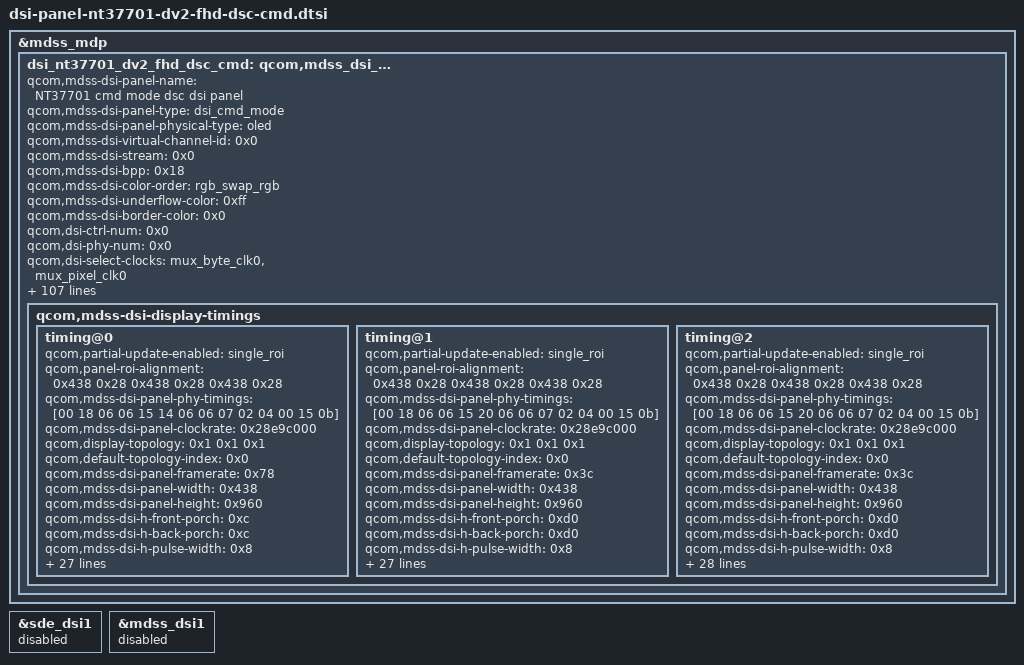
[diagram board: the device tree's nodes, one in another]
/* Copyright (c) 2014, Code Aurora Forum. All rights reserved.
 *
 * This program is free software; you can redistribute it and/or modify
 * it under the terms of the GNU General Public License version 2 and
 * only version 2 as published by the Free Software Foundation.
 *
 * This program is distributed in the hope that it will be useful,
 * but WITHOUT ANY WARRANTY; without even the implied warranty of
 * MERCHANTABILITY or FITNESS FOR A PARTICULAR PURPOSE.  See the
 * GNU General Public License for more details.
 */

&mdss_mdp {
    dsi_nt37701_dv2_fhd_dsc_cmd: qcom,mdss_dsi_nt37701_dv1_fhd_dsc_cmd {
        qcom,mdss-dsi-panel-name = "NT37701 cmd mode dsc dsi panel";
				qcom,mdss-dsi-panel-type = "dsi_cmd_mode";
				qcom,mdss-dsi-panel-physical-type = "oled";
				qcom,mdss-dsi-virtual-channel-id = <0x0>;
				qcom,mdss-dsi-stream = <0x0>;
				qcom,mdss-dsi-bpp = <0x18>;
				qcom,mdss-dsi-color-order = "rgb_swap_rgb";
				qcom,mdss-dsi-underflow-color = <0xff>;
				qcom,mdss-dsi-border-color = <0x0>;
				qcom,dsi-ctrl-num = <0x0>;
				qcom,dsi-phy-num = <0x0>;
				qcom,dsi-select-clocks = "mux_byte_clk0", "mux_pixel_clk0";
				qcom,mdss-dsi-traffic-mode = "burst_mode";
				qcom,mdss-dsi-lane-map = "lane_map_0123";
				qcom,mdss-dsi-bllp-eof-power-mode;
				qcom,mdss-dsi-bllp-power-mode;
				qcom,mdss-dsi-lane-0-state;
				qcom,mdss-dsi-lane-1-state;
				qcom,mdss-dsi-lane-2-state;
				qcom,mdss-dsi-lane-3-state;
				qcom,mdss-dsi-reset-sequence = <0x1 0xa 0x0 0x2 0x1 0xa>;
				lge,mdss-dsi-reset-keep-high-after-off-cmd = <0xb4>;
				qcom,mdss-dsi-dma-trigger = "trigger_sw";
				qcom,mdss-dsi-mdp-trigger = "none";
				qcom,mdss-dsi-te-pin-select = <0x1>;
				qcom,mdss-dsi-wr-mem-start = <0x2c>;
				qcom,mdss-dsi-wr-mem-continue = <0x3c>;
				qcom,mdss-dsi-te-dcs-command = <0x1>;
				qcom,mdss-dsi-lp11-init;
				qcom,mdss-dsi-tx-eot-append;
				qcom,ulps-enabled;
				qcom,mdss-pan-physical-width-dimension = <0x47>;
				qcom,mdss-pan-physical-height-dimension = <0x9d>;
				qcom,mdss-dsi-panel-hdr-enabled;
				qcom,mdss-dsi-panel-hdr-color-primaries = <0x3a20 0x3e3f 0x7eb3 0x40ab 0x3a61 0x78be 0x1e6e 0xd57>;
				qcom,mdss-dsi-panel-peak-brightness = <0x4c4b40>;
				qcom,mdss-dsi-panel-blackness-level = <0x17f6>;
				lge,blmap = <0x0 0x2c 0x2c 0x2c 0x2c 0x2c 0x2c 0x2c 0x2c 0x2c 0x2c 0x34 0x3b 0x43 0x4a 0x52 0x59 0x61 0x69 0x70 0x78 0x7f 0x87 0x8f 0x96 0x9e 0xa5 0xad 0xb4 0xbc 0xc4 0xcb 0xd3 0xda 0xe2 0xe9 0xf1 0xfd 0x109 0x115 0x121 0x12d 0x139 0x144 0x150 0x15c 0x168 0x174 0x180 0x18c 0x198 0x1a4 0x1b0 0x1bc 0x1c8 0x1d3 0x1df 0x1eb 0x1f7 0x203 0x20f 0x21b 0x22a 0x238 0x247 0x255 0x264 0x272 0x281 0x28f 0x29e 0x2ac 0x2bb 0x2ca 0x2d8 0x2e7 0x2f5 0x304 0x312 0x321 0x32f 0x33e 0x34e 0x35d 0x36d 0x378 0x388 0x398 0x3a7 0x3b7 0x3c7 0x3d7 0x3e6 0x3f6 0x406 0x416 0x426 0x435 0x445 0x455 0x465 0x475 0x484 0x494 0x4a4 0x4b4 0x4c3 0x4d3 0x4e3 0x4f0 0x4fe 0x50b 0x518 0x526 0x533 0x540 0x54e 0x55b 0x568 0x576 0x583 0x591 0x59e 0x5ab 0x5b9 0x5c6 0x5d3 0x5e1 0x5ee 0x5fb 0x609 0x616 0x623 0x631 0x63e 0x64e 0x65d 0x66d 0x67d 0x68c 0x69c 0x6ac 0x6b9 0x6c9 0x6d8 0x6e8 0x6f8 0x708 0x717 0x727 0x737 0x746 0x756 0x766 0x775 0x785 0x795 0x7a4 0x7b4 0x7c6 0x7d3 0x7e1 0x7ee 0x7fc 0x809 0x817 0x824 0x832 0x83f 0x84d 0x85a 0x868 0x875 0x882 0x890 0x89d 0x8ab 0x8b8 0x8c6 0x8d3 0x8e1 0x8ee 0x8fc 0x909 0x917 0x924 0x932 0x93f 0x94d 0x95a 0x968 0x975 0x983 0x990 0x99e 0x9ac 0x9b9 0x9c7 0x9d4 0x9e2 0x9ef 0x9fd 0xa0a 0xa18 0xa25 0xa33 0xa40 0xa4e 0xa5b 0xa68 0xa76 0xa83 0xa90 0xa9d 0xaab 0xab8 0xac5 0xad2 0xae0 0xaed 0xafa 0xb07 0xb15 0xb22 0xb2f 0xb3c 0xb4a 0xb57 0xb64 0xb71 0xb7f 0xb8c 0xb99 0xba8 0xbb7 0xbc6 0xbd5 0xbe4 0xbf3 0xc02 0xc11 0xc20 0xc2f 0xc3e 0xc4e 0xc5d 0xc6c 0xc7b 0xc8a 0xc99 0xca8 0xcb7 0xcc6 0xcd5 0xce4 0xcf3 0xcf7 0xcfc 0xd00 0xd04 0xd08 0xd0d 0xd11 0xd15 0xd19 0xd1e 0xd22 0xd26 0xd2a 0xd2f 0xd33 0xd37 0xd3b 0xd40 0xd44 0xd48 0xd4f 0xd55 0xd5c 0xd63 0xd69 0xd70 0xd77 0xd7d 0xd84 0xd8b 0xd91 0xd98 0xd9f 0xda5 0xdac 0xdb3 0xdb9 0xdc0 0xdc7 0xdcd 0xdd4 0xddb 0xde1 0xde8 0xdef 0xdf5 0xdfc 0xe03 0xe09 0xe10 0xe17 0xe1d 0xe24 0xe2b 0xe31 0xe38 0xe3f 0xe45 0xe4c 0xe53 0xe59 0xe60 0xe67 0xe6d 0xe74 0xe7b 0xe81 0xe88 0xe8f 0xe95 0xe9c 0xea3 0xea9 0xeb0 0xeb7 0xebd 0xec4 0xecb 0xed1 0xed8 0xedf 0xee5 0xeec 0xef3 0xef9 0xf00 0xf07 0xf0d 0xf14 0xf1b 0xf21 0xf28 0xf2f 0xf35 0xf3c 0xf3d 0xf3f 0xf40 0xf42 0xf43 0xf45 0xf46 0xf48 0xf49 0xf4b 0xf4c 0xf4e 0xf4f 0xf51 0xf52>;
				lge,blmap-daylight = <0x0 0x2c 0x2c 0x2c 0x2c 0x2c 0x2c 0x2c 0x2c 0x2c 0x2c 0x34 0x3b 0x43 0x4a 0x52 0x59 0x61 0x69 0x70 0x78 0x7f 0x87 0x8f 0x96 0x9e 0xa5 0xad 0xb4 0xbc 0xc4 0xcb 0xd3 0xda 0xe2 0xe9 0xf1 0xfd 0x109 0x115 0x121 0x12d 0x139 0x144 0x150 0x15c 0x168 0x174 0x180 0x18c 0x198 0x1a4 0x1b0 0x1bc 0x1c8 0x1d3 0x1df 0x1eb 0x1f7 0x203 0x20f 0x21b 0x22a 0x238 0x247 0x255 0x264 0x272 0x281 0x28f 0x29e 0x2ac 0x2bb 0x2ca 0x2d8 0x2e7 0x2f5 0x304 0x312 0x321 0x32f 0x33e 0x34e 0x35d 0x36d 0x378 0x388 0x398 0x3a7 0x3b7 0x3c7 0x3d7 0x3e6 0x3f6 0x406 0x416 0x426 0x435 0x445 0x455 0x465 0x475 0x484 0x494 0x4a4 0x4b4 0x4c3 0x4d3 0x4e3 0x4f0 0x4fe 0x50b 0x518 0x526 0x533 0x540 0x54e 0x55b 0x568 0x576 0x583 0x591 0x59e 0x5ab 0x5b9 0x5c6 0x5d3 0x5e1 0x5ee 0x5fb 0x609 0x616 0x623 0x631 0x63e 0x64e 0x65d 0x66d 0x67d 0x68c 0x69c 0x6ac 0x6b9 0x6c9 0x6d8 0x6e8 0x6f8 0x708 0x717 0x727 0x737 0x746 0x756 0x766 0x775 0x785 0x795 0x7a4 0x7b4 0x7c6 0x7d3 0x7e1 0x7ee 0x7fc 0x809 0x817 0x824 0x832 0x83f 0x84d 0x85a 0x868 0x875 0x882 0x890 0x89d 0x8ab 0x8b8 0x8c6 0x8d3 0x8e1 0x8ee 0x8fc 0x909 0x917 0x924 0x932 0x93f 0x94d 0x95a 0x968 0x975 0x983 0x990 0x99e 0x9ac 0x9b9 0x9c7 0x9d4 0x9e2 0x9ef 0x9fd 0xa0a 0xa18 0xa25 0xa33 0xa40 0xa4e 0xa5b 0xa68 0xa76 0xa83 0xa90 0xa9d 0xaab 0xab8 0xac5 0xad2 0xae0 0xaed 0xafa 0xb07 0xb15 0xb22 0xb2f 0xb3c 0xb4a 0xb57 0xb64 0xb71 0xb7f 0xb8c 0xb99 0xbc2 0xbec 0xc15 0xc3f 0xc68 0xc92 0xcbb 0xce4 0xd0e 0xd37 0xd61 0xd8a 0xdb4 0xddd 0xe07 0xe30 0xe59 0xe83 0xeac 0xed6 0xeff 0xf29 0xf52 0xf52 0xf52 0xf52 0xf52 0xf52 0xf52 0xf52 0xf52 0xf52 0xf52 0xf52 0xf52 0xf52 0xf52 0xf52 0xf52 0xf52 0xf52 0xf52 0xf52 0xf52 0xf52 0xf52 0xf52 0xf52 0xf52 0xf52 0xf52 0xf52 0xf52 0xf52 0xf52 0xf52 0xf52 0xf52 0xf52 0xf52 0xf52 0xf52 0xf52 0xf52 0xf52 0xf52 0xf52 0xf52 0xf52 0xf52 0xf52 0xf52 0xf52 0xf52 0xf52 0xf52 0xf52 0xf52 0xf52 0xf52 0xf52 0xf52 0xf52 0xf52 0xf52 0xf52 0xf52 0xf52 0xf52 0xf52 0xf52 0xf52 0xf52 0xf52 0xf52 0xf52 0xf52 0xf52 0xf52 0xf52 0xf52 0xf52 0xf52 0xf52 0xf52 0xf52 0xf52 0xf52 0xf52 0xf52 0xf52 0xf52 0xf52 0xf52 0xf52 0xf52 0xf52 0xf52 0xf52 0xf52 0xf52 0xf52 0xf52 0xf52 0xf52 0xf52 0xf52 0xf52 0xf52 0xf52 0xf52 0xf52 0xf52>;
				lge,blmap-hdr = <0x0 0x2c 0x2c 0x2c 0x2c 0x2c 0x2c 0x2c 0x2c 0x2c 0x2c 0x34 0x3b 0x43 0x4a 0x52 0x59 0x61 0x69 0x70 0x78 0x7f 0x87 0x8f 0x96 0x9e 0xa5 0xad 0xb4 0xbc 0xc4 0xcb 0xd3 0xda 0xe2 0xe9 0xf1 0xfd 0x109 0x115 0x121 0x12d 0x139 0x144 0x150 0x15c 0x168 0x174 0x180 0x18c 0x198 0x1a4 0x1b0 0x1bc 0x1c8 0x1d3 0x1df 0x1eb 0x1f7 0x203 0x20f 0x21b 0x22a 0x238 0x247 0x255 0x264 0x272 0x281 0x28f 0x29e 0x2ac 0x2bb 0x2ca 0x2d8 0x2e7 0x2f5 0x304 0x312 0x321 0x32f 0x33e 0x34e 0x35d 0x36d 0x378 0x388 0x398 0x3a7 0x3b7 0x3c7 0x3d7 0x3e6 0x3f6 0x406 0x416 0x426 0x435 0x445 0x455 0x465 0x475 0x484 0x494 0x4a4 0x4b4 0x4c3 0x4d3 0x4e3 0x4f0 0x4fe 0x50b 0x518 0x526 0x533 0x540 0x54e 0x55b 0x568 0x576 0x583 0x591 0x59e 0x5ab 0x5b9 0x5c6 0x5d3 0x5e1 0x5ee 0x5fb 0x609 0x616 0x623 0x631 0x63e 0x64e 0x65d 0x66d 0x67d 0x68c 0x69c 0x6ac 0x6b9 0x6c9 0x6d8 0x6e8 0x6f8 0x708 0x717 0x727 0x737 0x746 0x756 0x766 0x775 0x785 0x795 0x7a4 0x7b4 0x7c6 0x7d3 0x7e1 0x7ee 0x7fc 0x809 0x817 0x824 0x832 0x83f 0x84d 0x85a 0x868 0x875 0x882 0x890 0x89d 0x8ab 0x8b8 0x8c6 0x8d3 0x8e1 0x8ee 0x8fc 0x909 0x917 0x924 0x932 0x93f 0x94d 0x95a 0x968 0x975 0x983 0x990 0x99e 0x9ac 0x9b9 0x9c7 0x9d4 0x9e2 0x9ef 0x9fd 0xa0a 0xa18 0xa25 0xa33 0xa40 0xa4e 0xa5b 0xa68 0xa76 0xa83 0xa90 0xa9d 0xaab 0xab8 0xac5 0xad2 0xae0 0xaed 0xafa 0xb07 0xb15 0xb22 0xb2f 0xb3c 0xb4a 0xb57 0xb64 0xb71 0xb7f 0xb8c 0xb99 0xba8 0xbb7 0xbc6 0xbd5 0xbe4 0xbf3 0xc02 0xc11 0xc20 0xc2f 0xc3e 0xc4e 0xc5d 0xc6c 0xc7b 0xc8a 0xc99 0xca8 0xcb7 0xcc6 0xcd5 0xce4 0xcf3 0xcf7 0xcfc 0xd00 0xd04 0xd08 0xd0d 0xd11 0xd15 0xd19 0xd1e 0xd22 0xd26 0xd2a 0xd2f 0xd33 0xd37 0xd3b 0xd40 0xd44 0xd48 0xd4f 0xd55 0xd5c 0xd63 0xd69 0xd70 0xd77 0xd7d 0xd84 0xd8b 0xd91 0xd98 0xd9f 0xda5 0xdac 0xdb3 0xdb9 0xdc0 0xdc7 0xdcd 0xdd4 0xddb 0xde1 0xde8 0xdef 0xdf5 0xdfc 0xe03 0xe09 0xe10 0xe17 0xe1d 0xe24 0xe2b 0xe31 0xe38 0xe3f 0xe45 0xe4c 0xe53 0xe59 0xe60 0xe67 0xe6d 0xe74 0xe7b 0xe81 0xe88 0xe8f 0xe95 0xe9c 0xea3 0xea9 0xeb0 0xeb7 0xebd 0xec4 0xecb 0xed1 0xed8 0xedf 0xee5 0xeec 0xef3 0xef9 0xf00 0xf07 0xf0d 0xf14 0xf1b 0xf21 0xf28 0xf2f 0xf35 0xf3c 0xf3d 0xf3f 0xf40 0xf42 0xf43 0xf45 0xf46 0xf48 0xf49 0xf4b 0xf4c 0xf4e 0xf4f 0xf51 0xf52>;
				lge,blmap-hdr-daylight = <0x0 0x2c 0x2c 0x2c 0x2c 0x2c 0x2c 0x2c 0x2c 0x2c 0x2c 0x34 0x3b 0x43 0x4a 0x52 0x59 0x61 0x69 0x70 0x78 0x7f 0x87 0x8f 0x96 0x9e 0xa5 0xad 0xb4 0xbc 0xc4 0xcb 0xd3 0xda 0xe2 0xe9 0xf1 0xfd 0x109 0x115 0x121 0x12d 0x139 0x144 0x150 0x15c 0x168 0x174 0x180 0x18c 0x198 0x1a4 0x1b0 0x1bc 0x1c8 0x1d3 0x1df 0x1eb 0x1f7 0x203 0x20f 0x21b 0x22a 0x238 0x247 0x255 0x264 0x272 0x281 0x28f 0x29e 0x2ac 0x2bb 0x2ca 0x2d8 0x2e7 0x2f5 0x304 0x312 0x321 0x32f 0x33e 0x34e 0x35d 0x36d 0x378 0x388 0x398 0x3a7 0x3b7 0x3c7 0x3d7 0x3e6 0x3f6 0x406 0x416 0x426 0x435 0x445 0x455 0x465 0x475 0x484 0x494 0x4a4 0x4b4 0x4c3 0x4d3 0x4e3 0x4f0 0x4fe 0x50b 0x518 0x526 0x533 0x540 0x54e 0x55b 0x568 0x576 0x583 0x591 0x59e 0x5ab 0x5b9 0x5c6 0x5d3 0x5e1 0x5ee 0x5fb 0x609 0x616 0x623 0x631 0x63e 0x64e 0x65d 0x66d 0x67d 0x68c 0x69c 0x6ac 0x6b9 0x6c9 0x6d8 0x6e8 0x6f8 0x708 0x717 0x727 0x737 0x746 0x756 0x766 0x775 0x785 0x795 0x7a4 0x7b4 0x7c6 0x7d3 0x7e1 0x7ee 0x7fc 0x809 0x817 0x824 0x832 0x83f 0x84d 0x85a 0x868 0x875 0x882 0x890 0x89d 0x8ab 0x8b8 0x8c6 0x8d3 0x8e1 0x8ee 0x8fc 0x909 0x917 0x924 0x932 0x93f 0x94d 0x95a 0x968 0x975 0x983 0x990 0x99e 0x9ac 0x9b9 0x9c7 0x9d4 0x9e2 0x9ef 0x9fd 0xa0a 0xa18 0xa25 0xa33 0xa40 0xa4e 0xa5b 0xa68 0xa76 0xa83 0xa90 0xa9d 0xaab 0xab8 0xac5 0xad2 0xae0 0xaed 0xafa 0xb07 0xb15 0xb22 0xb2f 0xb3c 0xb4a 0xb57 0xb64 0xb71 0xb7f 0xb8c 0xb99 0xbc2 0xbec 0xc15 0xc3f 0xc68 0xc92 0xcbb 0xce4 0xd0e 0xd37 0xd61 0xd8a 0xdb4 0xddd 0xe07 0xe30 0xe59 0xe83 0xeac 0xed6 0xeff 0xf29 0xf52 0xf52 0xf52 0xf52 0xf52 0xf52 0xf52 0xf52 0xf52 0xf52 0xf52 0xf52 0xf52 0xf52 0xf52 0xf52 0xf52 0xf52 0xf52 0xf52 0xf52 0xf52 0xf52 0xf52 0xf52 0xf52 0xf52 0xf52 0xf52 0xf52 0xf52 0xf52 0xf52 0xf52 0xf52 0xf52 0xf52 0xf52 0xf52 0xf52 0xf52 0xf52 0xf52 0xf52 0xf52 0xf52 0xf52 0xf52 0xf52 0xf52 0xf52 0xf52 0xf52 0xf52 0xf52 0xf52 0xf52 0xf52 0xf52 0xf52 0xf52 0xf52 0xf52 0xf52 0xf52 0xf52 0xf52 0xf52 0xf52 0xf52 0xf52 0xf52 0xf52 0xf52 0xf52 0xf52 0xf52 0xf52 0xf52 0xf52 0xf52 0xf52 0xf52 0xf52 0xf52 0xf52 0xf52 0xf52 0xf52 0xf52 0xf52 0xf52 0xf52 0xf52 0xf52 0xf52 0xf52 0xf52 0xf52 0xf52 0xf52 0xf52 0xf52 0xf52 0xf52 0xf52 0xf52 0xf52 0xf52 0xf52 0xf52>;
				lge,blmap-ex = <0x0 0x154 0x154 0x154 0x154 0x154 0x154 0x154 0x154 0x154 0x16a 0x180 0x196 0x1ac 0x1c2 0x1d8 0x1ee 0x204 0x21a 0x230 0x246 0x25c 0x272 0x288 0x29e 0x2b4 0x2ca 0x2e0 0x2f6 0x30c 0x322 0x338 0x34e 0x364 0x37a 0x390 0x3a6 0x3ba 0x3ce 0x3e2 0x3f6 0x40a 0x41e 0x431 0x445 0x459 0x46d 0x481 0x495 0x4a9 0x4bd 0x4d1 0x4e5 0x4f9 0x50d 0x521 0x534 0x548 0x55c 0x570 0x584 0x598 0x5ac 0x5c0 0x5d4 0x5e8 0x5fc 0x610 0x624 0x637 0x64b 0x65f 0x673 0x687 0x69b 0x6af 0x6d2 0x6f4 0x717 0x73a 0x75d 0x77f 0x7a2 0x7c5 0x7e8 0x80a 0x82d 0x850 0x872 0x895 0x8b8 0x8db 0x8fd 0x920 0x943 0x966 0x988 0x9ab 0x9ca 0x9e8 0xa07 0xa25 0xa44 0xa63 0xa81 0xaa0 0xabf 0xadd 0xafc 0xb1a 0xb39 0xb58 0xb76 0xb95 0xbb3 0xbd2 0xbe9 0xc01 0xc18 0xc30 0xc47 0xc5f 0xc76 0xc8e 0xca5 0xcbd 0xcd4 0xcec 0xd03 0xd1b 0xd32 0xd4a 0xd61 0xd79 0xd90 0xdc4 0xdf8 0xe2c 0xe5f 0xe93 0xec7 0xed7 0xee8 0xef8 0xf09 0xf19 0xf2a 0xf3a 0xf4a 0xf5b 0xf6b 0xf7c 0xf8c 0xf9c 0xfad 0xfbd 0xfce 0xfde 0xfef 0xfff 0xfff 0xfff 0xfff 0xfff 0xfff 0xfff 0xfff 0xfff 0xfff 0xfff 0xfff 0xfff 0xfff 0xfff 0xfff 0xfff 0xfff 0xfff 0xfff 0xfff 0xfff 0xfff 0xfff 0xfff 0xfff 0xfff 0xfff 0xfff 0xfff 0xfff 0xfff 0xfff 0xfff 0xfff 0xfff 0xfff 0xfff 0xfff 0xfff 0xfff 0xfff 0xfff 0xfff 0xfff 0xfff 0xfff 0xfff 0xfff 0xfff 0xfff 0xfff 0xfff 0xfff 0xfff 0xfff 0xfff 0xfff 0xfff 0xfff 0xfff 0xfff 0xfff 0xfff 0xfff 0xfff 0xfff 0xfff 0xfff 0xfff 0xfff 0xfff 0xfff 0xfff 0xfff 0xfff 0xfff 0xfff 0xfff 0xfff 0xfff 0xfff 0xfff 0xfff 0xfff 0xfff 0xfff 0xfff 0xfff 0xfff 0xfff 0xfff 0xfff 0xfff 0xfff 0xfff 0xfff 0xfff 0xfff 0xfff 0xfff 0xfff 0xfff 0xfff 0xfff 0xfff 0xfff 0xfff 0xfff 0xfff 0xfff 0xfff 0xfff 0xfff 0xfff 0xfff 0xfff>;
				lge,use-vr-lp-mode;
				lge,mdss-dsi-vr-lp-mode-on-command = [39 00 00 00 00 00 06 f0 55 aa 52 08 00 39 00 00 00 00 00 10 b2 11 00 20 20 00 08 08 00 00 40 30 00 00 00 00 15 00 00 00 00 00 02 6f 0f 39 00 00 00 00 00 0c b2 30 20 24 24 24 24 2f ff 00 00 00 39 01 00 00 00 00 06 f0 55 aa 52 00 00];
				lge,mdss-dsi-vr-lp-mode-off-command = [39 00 00 00 00 00 06 f0 55 aa 52 08 00 39 00 00 00 00 00 10 b2 01 00 20 20 00 08 08 00 00 40 30 00 00 00 00 15 00 00 00 00 00 02 6f 0f 39 00 00 00 00 00 0c b2 30 20 25 89 25 89 2f ff 00 00 00 39 01 00 00 00 00 06 f0 55 aa 52 00 00];
				lge,mdss-dsi-vr-lp-command-state = "dsi_lp_mode";
				lge,blmap-vr = <0x0 0x424>;
				lge,use-color-manager;
				lge,color-manager-default-status = <0x1>;
				lge,mdss-dsi-color-manager-mode-table = <0x0 0x1 0x1 0x1 0x2 0x1 0x3 0x1>;
				lge,mdss-dsi-disp-ctrl-command-1 = [15 01 00 00 00 00 02 55 00];
				lge,mdss-dsi-disp-ctrl-command-1-state = "dsi_lp_mode";
				lge,mdss-dsi-saturation-command = [39 00 00 00 00 00 06 f0 55 aa 52 08 00 39 00 00 00 00 00 2e d1 35 35 35 35 32 30 30 30 32 2d 2d 29 29 32 32 35 35 35 35 33 32 33 35 35 03 01 01 01 01 01 01 01 02 01 01 01 01 06 0c 03 09 0f 68 88 00 39 01 00 00 00 00 06 f0 55 aa 52 00 00];
				lge,mdss-dsi-saturation-command-state = "dsi_hs_mode";
				lge,mdss-dsi-hue-command = [39 00 00 00 00 00 06 f0 55 aa 52 08 00 39 00 00 00 00 00 34 d2 77 0c 40 80 80 8e 80 80 80 80 40 40 40 80 80 80 ad ad a0 80 80 80 80 80 80 80 80 80 80 80 80 80 80 80 80 80 80 80 80 80 80 80 80 80 80 80 80 80 80 80 80 39 01 00 00 00 00 06 f0 55 aa 52 00 00];
				lge,mdss-dsi-hue-command-state = "dsi_hs_mode";
				lge,mdss-dsi-sharpness-command = <0x39000000 0x6f0 0x55aa5208 0x390000 0x7 0xd3020000 0x1100039 0x1000000 0x6f055 0xaa520000>;
				lge,mdss-dsi-sharpness-command-state = "dsi_hs_mode";
				lge,mdss-dsi-cm-natural = <0x39000000 0x6f0 0x55aa5208 0x150000 0x2 0x6f003900 0x0 0x13ce0040 0x4040403d 0x3d3d3d40 0x40404040 0x40404040 0x15000000 0x26f 0x13390000 0x12 0xce454545 0x45454545 0x45454545 0x45454545 0x45401500 0x0 0x26f2439 0x0 0x12ce42 0x42424242 0x42424242 0x42424242 0x42424040 0x15000000 0x26f 0x35390000 0x12 0xce404040 0x40404040 0x40404040 0x40404040 0x40403900 0x0 0x2ed13233 0x32353230 0x302f2d2d 0x2d292929 0x32353535 0x35333233 0x35350301 0x1010101 0x1010201 0x1010106 0xc03090f 0x68880039 0x0 0x34d277 0xc408080 0x7f808080 0x80808080 0x808080a8 0xa8a08080 0x80808080 0x80808080 0x80808080 0x80804040 0x80808080 0x80808080 0x80808080 0x80803900 0x0 0x7d30000 0x0 0x39000000 0x6f0 0x55aa5208 0x7390000 0x3 0xc0010a39 0x1000000 0x6f055 0xaa520000>;
				lge,mdss-dsi-cm-natural-state = "dsi_hs_mode";
				lge,mdss-dsi-cm-vivid = <0x39000000 0x6f0 0x55aa5208 0x150000 0x2 0x6f003900 0x0 0x13ce0040 0x40404040 0x40404040 0x40404040 0x40404040 0x15000000 0x26f 0x13390000 0x12 0xce404040 0x40404040 0x40404040 0x40404040 0x40401500 0x0 0x26f2439 0x0 0x12ce40 0x40404040 0x40404040 0x40404040 0x40404040 0x15000000 0x26f 0x35390000 0x12 0xce404040 0x40404040 0x40404040 0x40404040 0x40403900 0x0 0x2ed15035 0x35355050 0x50505050 0x50505050 0x50505050 0x50505050 0x50500101 0x1010101 0x1010101 0x1010006 0xc03090f 0x68880039 0x0 0x34d277 0xc408080 0x95808080 0x80808080 0x80808080 0x80808080 0x80808080 0x80808080 0x80808080 0x80808080 0x80808080 0x80808080 0x80808080 0x80803900 0x0 0x7d30000 0x0 0x39000000 0x6f0 0x55aa5208 0x7390000 0x3 0xc0010a39 0x1000000 0x6f055 0xaa520000>;
				lge,mdss-dsi-cm-vivid-state = "dsi_hs_mode";
				lge,mdss-dsi-cm-cinema = <0x39000000 0x6f0 0x55aa5208 0x150000 0x2 0x6f003900 0x0 0x13ce0040 0x40444444 0x44444444 0x44444444 0x44444440 0x15000000 0x26f 0x13390000 0x12 0xce404040 0x40404040 0x40404040 0x40404040 0x40401500 0x0 0x26f2439 0x0 0x12ce43 0x43434343 0x43434343 0x43434848 0x48484850 0x15000000 0x26f 0x35390000 0x12 0xce444444 0x44444444 0x44444444 0x44444444 0x44453900 0x0 0x2ed13535 0x35353535 0x37373835 0x302c2c2c 0x30323535 0x35353534 0x33354414 0x11111111 0x11151111 0x21440006 0xc03090f 0x68880039 0x0 0x34d277 0xc408080 0x8d858080 0x70605060 0x7a808080 0x8a8a8a80 0x7b7b7876 0x74808080 0x80808080 0x80808080 0x80808080 0x80808080 0x80808080 0x80803900 0x0 0x7d30000 0x0 0x39000000 0x6f0 0x55aa5208 0x7390000 0x3 0xc0010a39 0x1000000 0x6f055 0xaa520000>;
				lge,mdss-dsi-cm-cinema-state = "dsi_hs_mode";
				lge,mdss-dsi-ve-on-command = [39 00 00 00 00 00 06 f0 55 aa 52 08 00 39 00 00 00 00 00 2e d1 40 40 40 40 40 40 40 40 40 40 40 40 40 40 40 40 40 40 40 40 40 40 40 40 03 01 01 01 01 01 01 01 02 01 01 01 00 06 0c 03 09 0f 68 88 00 39 01 00 00 00 00 06 f0 55 aa 52 00 00];
				lge,mdss-dsi-ve-on-command-state = "dsi_hs_mode";
				lge,fps-switch-enabled;
				lge,mdss-dsi-switch-fps-ctrl-command = [39 01 00 00 00 00 02 2f 00];
				lge,mdss-dsi-switch-fps-ctrl-command-state = "dsi_lp_mode";
				lge,disp-br-ctrl-ext-supported;
				lge,ddic-dsi-br-ctrl-ext-command = <0x39010000 0x551 0x0>;
				lge,mdss-dsi-nolp-command = [39 00 00 00 00 00 06 f0 55 aa 52 08 00 39 00 00 00 00 00 02 6f 0b 39 00 00 00 00 00 04 b5 4e 29 50 39 01 00 00 00 00 06 f0 55 aa 52 00 00 39 01 00 00 00 00 02 65 00 05 01 00 00 00 00 01 38 05 01 00 00 00 00 01 2c];
				lge,mdss-dsi-nolp-command-state = "dsi_lp_mode";
				lge,mdss-dsi-lp2-command = <0x39000000 0x6f0 0x55aa5208 0x390000 0x2 0x6f0b3900 0x0 0x4b54e29 0x51150000 0x2 0x55003900 0x0 0x6f055aa 0x52080739 0x0 0x3c001 0x2390100 0x6 0xf055aa52 0x3901 0x0 0x22f0105 0x1000040 0x13939 0x1000000 0x26500>;
				lge,mdss-dsi-lp2-command-state = "dsi_lp_mode";
				lge,send-partial-update-cmds-to-hs;
				qcom,panel-supply-entries = <0x11>;
				qcom,mdss-dsi-bl-pmic-control-type = "bl_ctrl_dcs";
				qcom,mdss-dsi-bl-min-level = <0x3>;
				qcom,mdss-dsi-bl-max-level = <0xfff>;
				qcom,mdss-brightness-max-level = <0x16d>;
				qcom,platform-te-gpio = <0xffffffff 0x52 0x0>;
				qcom,platform-reset-gpio = <0xffffffff 0x18 0x0>;
				qcom,esd-check-enabled;
				qcom,mdss-dsi-panel-status-check-mode = "te_signal_check";
				lge,dcs-brightness-bigendian;
				lge,default-brightness = <0x8a>;
				lge,man-name = "BOE";
				lge,ddic-name = "nt37701";
				lge,use-labibb;
				phandle = <0x13d>;

				qcom,mdss-dsi-display-timings {

					timing@0 {
						qcom,partial-update-enabled = "single_roi";
						qcom,panel-roi-alignment = <0x438 0x28 0x438 0x28 0x438 0x28>;
						qcom,mdss-dsi-panel-phy-timings = [00 18 06 06 15 14 06 06 07 02 04 00 15 0b];
						qcom,mdss-dsi-panel-clockrate = <0x28e9c000>;
						qcom,display-topology = <0x1 0x1 0x1>;
						qcom,default-topology-index = <0x0>;
						qcom,mdss-dsi-panel-framerate = <0x78>;
						qcom,mdss-dsi-panel-width = <0x438>;
						qcom,mdss-dsi-panel-height = <0x960>;
						qcom,mdss-dsi-h-front-porch = <0xc>;
						qcom,mdss-dsi-h-back-porch = <0xc>;
						qcom,mdss-dsi-h-pulse-width = <0x8>;
						qcom,mdss-dsi-h-sync-skew = <0x0>;
						qcom,mdss-dsi-v-back-porch = <0xe>;
						qcom,mdss-dsi-v-front-porch = <0x10>;
						qcom,mdss-dsi-v-pulse-width = <0x2>;
						qcom,mdss-dsi-h-left-border = <0x0>;
						qcom,mdss-dsi-h-right-border = <0x0>;
						qcom,mdss-dsi-v-top-border = <0x0>;
						qcom,mdss-dsi-v-bottom-border = <0x0>;
						qcom,mdss-dsi-h-sync-pulse = <0x0>;
						qcom,mdss-dsi-on-command = [39 01 00 00 00 00 06 f0 55 aa 52 00 04 39 01 00 00 00 00 07 b4 01 07 8c 00 22 09 39 01 00 00 00 00 01 35 39 01 00 00 00 00 02 53 20 39 01 00 00 00 00 05 51 0d bb 0f fe 39 01 00 00 00 00 05 2a 00 00 04 37 39 01 00 00 00 00 05 2b 00 00 09 5f 39 01 00 00 00 00 02 03 01 39 01 00 00 00 00 02 90 01 39 01 00 00 00 00 13 91 89 28 00 28 c2 00 03 1c 05 2d 00 0f 02 77 01 46 10 f0 39 01 00 00 00 00 01 2c 39 01 00 00 00 00 02 82 a6 39 01 00 00 00 00 06 f0 55 aa 52 08 00 39 01 00 00 00 00 19 cc 40 40 40 40 40 40 40 40 40 40 40 40 40 40 40 40 40 50 60 70 58 68 78 77 15 01 00 00 00 00 02 6f 46 39 01 00 00 00 00 12 ce 40 40 40 40 40 40 40 40 40 40 40 40 40 40 40 40 40 15 01 00 00 00 00 02 6f 57 39 01 00 00 00 00 12 ce 40 40 40 40 40 40 40 40 40 40 40 40 40 40 40 40 40 15 01 00 00 00 00 02 6f 00 39 01 00 00 00 00 03 d0 77 00 15 01 00 00 00 00 02 6f 01 39 01 00 00 00 00 03 d4 00 00 39 01 00 00 00 00 19 de 00 00 00 00 00 00 00 00 00 00 00 00 10 00 00 00 00 00 00 00 10 00 00 00 39 01 00 00 00 00 06 f0 55 aa 52 00 00 39 01 00 00 00 00 02 2f 02 05 01 00 00 78 00 01 11 05 01 00 00 00 00 01 29];
						qcom,mdss-dsi-off-command = [39 01 00 00 00 00 06 f0 55 aa 52 08 01 39 01 00 00 00 00 02 ce 0c 39 01 00 00 00 00 06 f0 55 aa 52 00 00 05 01 00 00 78 00 01 28 05 01 00 00 96 00 01 10];
						qcom,compression-mode = "dsc";
						qcom,mdss-dsc-version = <0x11>;
						qcom,mdss-dsc-scr-version = <0x0>;
						qcom,mdss-dsc-slice-height = <0x28>;
						qcom,mdss-dsc-slice-width = <0x438>;
						qcom,mdss-dsc-slice-per-pkt = <0x1>;
						qcom,mdss-dsc-bit-per-component = <0x8>;
						qcom,mdss-dsc-bit-per-pixel = <0x8>;
						qcom,mdss-dsc-encoders = <0x1>;
						qcom,mdss-dsc-block-prediction-enable;
						qcom,mdss-dsi-on-command-state = "dsi_lp_mode";
						qcom,mdss-dsi-off-command-state = "dsi_lp_mode";
						qcom,mode-control-dsi-state = "dsi_lp_mode";
						qcom,mdss-dsi-pps-command-state = "dsi_hs_mode";
					};

					timing@1 {
						qcom,partial-update-enabled = "single_roi";
						qcom,panel-roi-alignment = <0x438 0x28 0x438 0x28 0x438 0x28>;
						qcom,mdss-dsi-panel-phy-timings = [00 18 06 06 15 20 06 06 07 02 04 00 15 0b];
						qcom,mdss-dsi-panel-clockrate = <0x28e9c000>;
						qcom,display-topology = <0x1 0x1 0x1>;
						qcom,default-topology-index = <0x0>;
						qcom,mdss-dsi-panel-framerate = <0x3c>;
						qcom,mdss-dsi-panel-width = <0x438>;
						qcom,mdss-dsi-panel-height = <0x960>;
						qcom,mdss-dsi-h-front-porch = <0xd0>;
						qcom,mdss-dsi-h-back-porch = <0xd0>;
						qcom,mdss-dsi-h-pulse-width = <0x8>;
						qcom,mdss-dsi-h-sync-skew = <0x0>;
						qcom,mdss-dsi-v-back-porch = <0xe>;
						qcom,mdss-dsi-v-front-porch = <0x10>;
						qcom,mdss-dsi-v-pulse-width = <0x2>;
						qcom,mdss-dsi-h-left-border = <0x0>;
						qcom,mdss-dsi-h-right-border = <0x0>;
						qcom,mdss-dsi-v-top-border = <0x0>;
						qcom,mdss-dsi-v-bottom-border = <0x0>;
						qcom,mdss-dsi-h-sync-pulse = <0x0>;
						qcom,mdss-dsi-on-command = [39 01 00 00 00 00 06 f0 55 aa 52 00 04 39 01 00 00 00 00 07 b4 01 07 8c 00 22 09 39 01 00 00 00 00 01 35 39 01 00 00 00 00 02 53 20 39 01 00 00 00 00 05 51 0d bb 0f fe 39 01 00 00 00 00 05 2a 00 00 04 37 39 01 00 00 00 00 05 2b 00 00 09 5f 39 01 00 00 00 00 02 03 01 39 01 00 00 00 00 02 90 01 39 01 00 00 00 00 13 91 89 28 00 28 c2 00 03 1c 05 2d 00 0f 02 77 01 46 10 f0 39 01 00 00 00 00 01 2c 39 01 00 00 00 00 02 82 a6 39 01 00 00 00 00 06 f0 55 aa 52 08 00 39 01 00 00 00 00 19 cc 40 40 40 40 40 40 40 40 40 40 40 40 40 40 40 40 40 50 60 70 58 68 78 77 15 01 00 00 00 00 02 6f 46 39 01 00 00 00 00 12 ce 40 40 40 40 40 40 40 40 40 40 40 40 40 40 40 40 40 15 01 00 00 00 00 02 6f 57 39 01 00 00 00 00 12 ce 40 40 40 40 40 40 40 40 40 40 40 40 40 40 40 40 40 15 01 00 00 00 00 02 6f 00 39 01 00 00 00 00 03 d0 77 00 15 01 00 00 00 00 02 6f 01 39 01 00 00 00 00 03 d4 00 00 39 01 00 00 00 00 19 de 00 00 00 00 00 00 00 00 00 00 00 00 10 00 00 00 00 00 00 00 10 00 00 00 39 01 00 00 00 00 06 f0 55 aa 52 00 00 39 01 00 00 00 00 02 2f 01 05 01 00 00 78 00 01 11 05 01 00 00 00 00 01 29];
						qcom,mdss-dsi-off-command = [39 01 00 00 00 00 06 f0 55 aa 52 08 01 39 01 00 00 00 00 02 ce 0c 39 01 00 00 00 00 06 f0 55 aa 52 00 00 05 01 00 00 78 00 01 28 05 01 00 00 96 00 01 10];
						qcom,compression-mode = "dsc";
						qcom,mdss-dsc-version = <0x11>;
						qcom,mdss-dsc-scr-version = <0x0>;
						qcom,mdss-dsc-slice-height = <0x28>;
						qcom,mdss-dsc-slice-width = <0x438>;
						qcom,mdss-dsc-slice-per-pkt = <0x1>;
						qcom,mdss-dsc-bit-per-component = <0x8>;
						qcom,mdss-dsc-bit-per-pixel = <0x8>;
						qcom,mdss-dsc-encoders = <0x1>;
						qcom,mdss-dsc-block-prediction-enable;
						qcom,mdss-dsi-on-command-state = "dsi_lp_mode";
						qcom,mdss-dsi-off-command-state = "dsi_lp_mode";
						qcom,mode-control-dsi-state = "dsi_lp_mode";
						qcom,mdss-dsi-pps-command-state = "dsi_hs_mode";
					};

					timing@2 {
						qcom,partial-update-enabled = "single_roi";
						qcom,panel-roi-alignment = <0x438 0x28 0x438 0x28 0x438 0x28>;
						qcom,mdss-dsi-panel-phy-timings = [00 18 06 06 15 20 06 06 07 02 04 00 15 0b];
						qcom,mdss-dsi-panel-clockrate = <0x28e9c000>;
						qcom,display-topology = <0x1 0x1 0x1>;
						qcom,default-topology-index = <0x0>;
						qcom,mdss-dsi-panel-framerate = <0x3c>;
						qcom,mdss-dsi-panel-width = <0x438>;
						qcom,mdss-dsi-panel-height = <0x960>;
						qcom,mdss-dsi-h-front-porch = <0xd0>;
						qcom,mdss-dsi-h-back-porch = <0xd0>;
						qcom,mdss-dsi-h-pulse-width = <0x8>;
						qcom,mdss-dsi-h-sync-skew = <0x0>;
						qcom,mdss-dsi-v-back-porch = <0xe>;
						qcom,mdss-dsi-v-front-porch = <0x10>;
						qcom,mdss-dsi-v-pulse-width = <0x2>;
						qcom,mdss-dsi-h-left-border = <0x0>;
						qcom,mdss-dsi-h-right-border = <0x0>;
						qcom,mdss-dsi-v-top-border = <0x0>;
						qcom,mdss-dsi-v-bottom-border = <0x0>;
						qcom,mdss-dsi-h-sync-pulse = <0x0>;
						lge,mdss-dsi-panel-framerate-div = <0x2>;
						qcom,mdss-dsi-on-command = [39 01 00 00 00 00 06 f0 55 aa 52 00 04 39 01 00 00 00 00 07 b4 01 07 8c 00 22 09 39 01 00 00 00 00 01 35 39 01 00 00 00 00 02 53 20 39 01 00 00 00 00 05 51 0d bb 0f fe 39 01 00 00 00 00 05 2a 00 00 04 37 39 01 00 00 00 00 05 2b 00 00 09 5f 39 01 00 00 00 00 02 03 01 39 01 00 00 00 00 02 90 01 39 01 00 00 00 00 13 91 89 28 00 28 c2 00 03 1c 05 2d 00 0f 02 77 01 46 10 f0 39 01 00 00 00 00 01 2c 39 01 00 00 00 00 02 82 a6 39 01 00 00 00 00 06 f0 55 aa 52 08 00 39 01 00 00 00 00 19 cc 40 40 40 40 40 40 40 40 40 40 40 40 40 40 40 40 40 50 60 70 58 68 78 77 15 01 00 00 00 00 02 6f 46 39 01 00 00 00 00 12 ce 40 40 40 40 40 40 40 40 40 40 40 40 40 40 40 40 40 15 01 00 00 00 00 02 6f 57 39 01 00 00 00 00 12 ce 40 40 40 40 40 40 40 40 40 40 40 40 40 40 40 40 40 15 01 00 00 00 00 02 6f 00 39 01 00 00 00 00 03 d0 77 00 15 01 00 00 00 00 02 6f 01 39 01 00 00 00 00 03 d4 00 00 39 01 00 00 00 00 19 de 00 00 00 00 00 00 00 00 00 00 00 00 10 00 00 00 00 00 00 00 10 00 00 00 39 01 00 00 00 00 06 f0 55 aa 52 00 00 39 01 00 00 00 00 02 2f 01 05 01 00 00 78 00 01 11 05 01 00 00 00 00 01 29];
						qcom,mdss-dsi-off-command = [39 01 00 00 00 00 06 f0 55 aa 52 08 01 39 01 00 00 00 00 02 ce 0c 39 01 00 00 00 00 06 f0 55 aa 52 00 00 05 01 00 00 78 00 01 28 05 01 00 00 96 00 01 10];
						qcom,compression-mode = "dsc";
						qcom,mdss-dsc-version = <0x11>;
						qcom,mdss-dsc-scr-version = <0x0>;
						qcom,mdss-dsc-slice-height = <0x28>;
						qcom,mdss-dsc-slice-width = <0x438>;
						qcom,mdss-dsc-slice-per-pkt = <0x1>;
						qcom,mdss-dsc-bit-per-component = <0x8>;
						qcom,mdss-dsc-bit-per-pixel = <0x8>;
						qcom,mdss-dsc-encoders = <0x1>;
						qcom,mdss-dsc-block-prediction-enable;
						qcom,mdss-dsi-on-command-state = "dsi_lp_mode";
						qcom,mdss-dsi-off-command-state = "dsi_lp_mode";
						qcom,mode-control-dsi-state = "dsi_lp_mode";
						qcom,mdss-dsi-pps-command-state = "dsi_hs_mode";
				};
			};
		};
	};

&sde_dsi1 {
	status = "disabled";
};

&mdss_dsi1 {
	status = "disabled";
};
